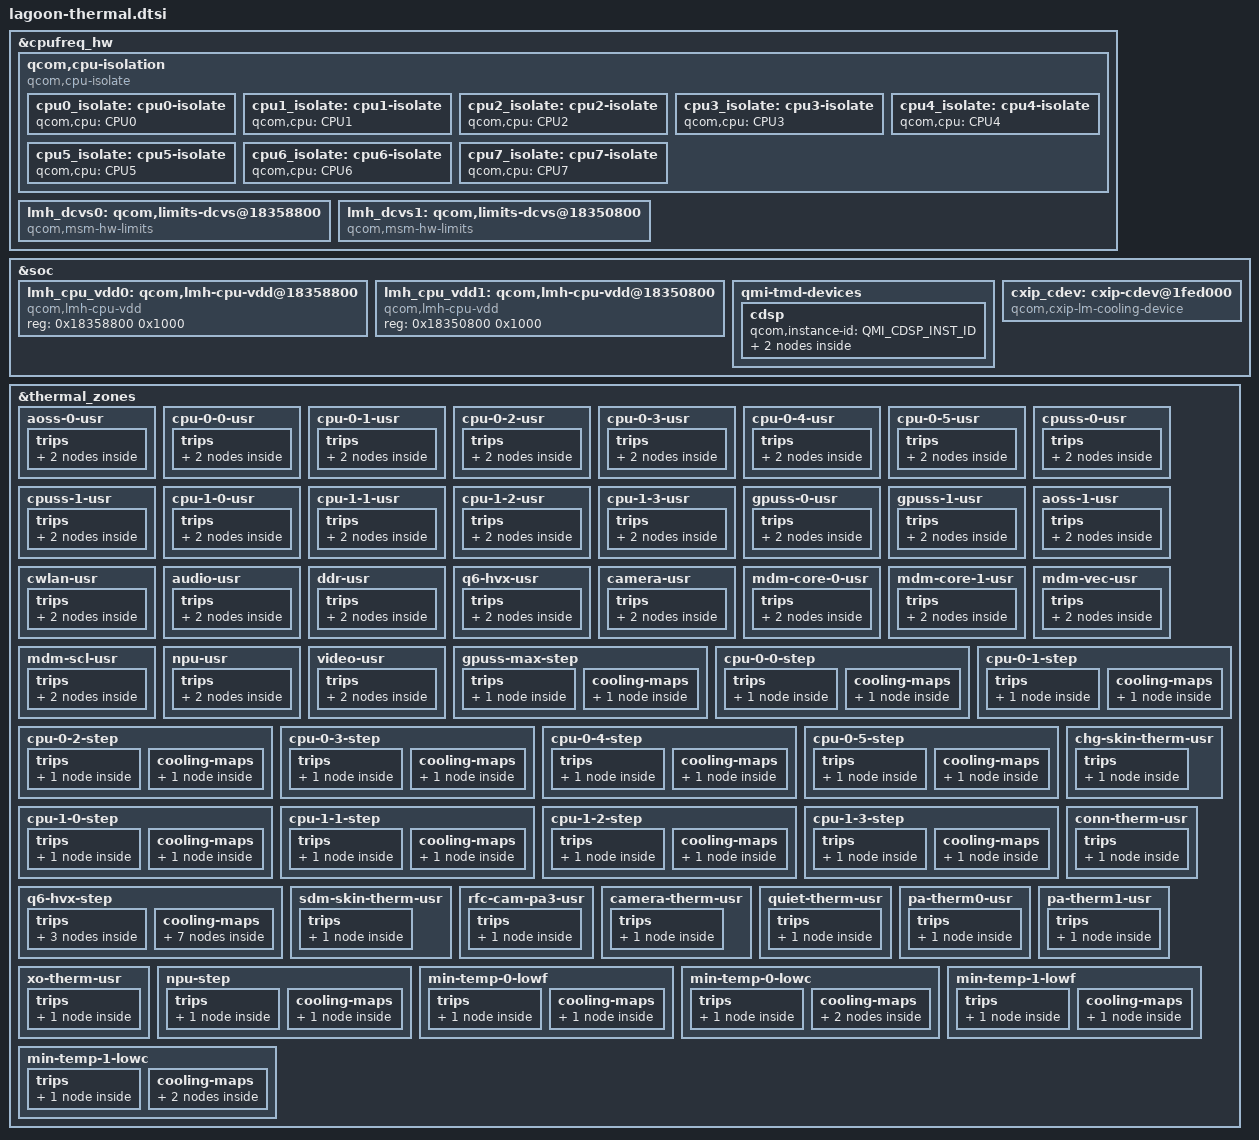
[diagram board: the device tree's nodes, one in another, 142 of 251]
#include <dt-bindings/thermal/thermal.h>
#include "sdxprairie-thermal-integrated.dtsi"

&cpufreq_hw {
	#address-cells = <1>;
	#size-cells = <1>;
	qcom,cpu-isolation {
		compatible = "qcom,cpu-isolate";
		cpu0_isolate: cpu0-isolate {
			qcom,cpu = <&CPU0>;
			#cooling-cells = <2>;
		};

		cpu1_isolate: cpu1-isolate {
			qcom,cpu = <&CPU1>;
			#cooling-cells = <2>;
		};

		cpu2_isolate: cpu2-isolate {
			qcom,cpu = <&CPU2>;
			#cooling-cells = <2>;
		};

		cpu3_isolate: cpu3-isolate {
			qcom,cpu = <&CPU3>;
			#cooling-cells = <2>;
		};

		cpu4_isolate: cpu4-isolate {
			qcom,cpu = <&CPU4>;
			#cooling-cells = <2>;
		};

		cpu5_isolate: cpu5-isolate {
			qcom,cpu = <&CPU5>;
			#cooling-cells = <2>;
		};

		cpu6_isolate: cpu6-isolate {
			qcom,cpu = <&CPU6>;
			#cooling-cells = <2>;
		};

		cpu7_isolate: cpu7-isolate {
			qcom,cpu = <&CPU7>;
			#cooling-cells = <2>;
		};
	};

	lmh_dcvs0: qcom,limits-dcvs@18358800 {
		compatible = "qcom,msm-hw-limits";
		interrupts = <GIC_SPI 32 IRQ_TYPE_LEVEL_HIGH>;
		qcom,affinity = <0>;
		reg = <0x18358800 0x1000>,
			<0x18323000 0x1000>;
		qcom,no-cooling-device-register;
	};

	lmh_dcvs1: qcom,limits-dcvs@18350800 {
		compatible = "qcom,msm-hw-limits";
		interrupts = <GIC_SPI 33 IRQ_TYPE_LEVEL_HIGH>;
		qcom,affinity = <1>;
		reg = <0x18350800 0x1000>,
			<0x18325800 0x1000>;
		qcom,no-cooling-device-register;
	};
};

&soc {
	lmh_cpu_vdd0: qcom,lmh-cpu-vdd@18358800 {
		compatible = "qcom,lmh-cpu-vdd";
		reg =  <0x18358800 0x1000>;
		#cooling-cells = <2>;
	};

	lmh_cpu_vdd1: qcom,lmh-cpu-vdd@18350800 {
		compatible = "qcom,lmh-cpu-vdd";
		reg =  <0x18350800 0x1000>;
		#cooling-cells = <2>;
	};

	qmi-tmd-devices {
		cdsp {
			qcom,instance-id = <QMI_CDSP_INST_ID>;

			cdsp_sw: cdsp {
				qcom,qmi-dev-name = "cdsp_sw";
				#cooling-cells = <2>;
			};

			cdsp_hw: hvx {
				qcom,qmi-dev-name = "cdsp_hw";
				#cooling-cells = <2>;
			};
		};
	};

	cxip_cdev: cxip-cdev@1fed000 {
		compatible = "qcom,cxip-lm-cooling-device";
		reg = <0x1fed000 0x10060>;
		qcom,thermal-client-offset = <0x8000>;
		qcom,bypass-client-list = <0xe00c 0xf00c 0x1000c 0x1001c
					0x1002c 0x1003c 0x1004c 0x1005c>;
		#cooling-cells = <2>;
	};
};

&thermal_zones {
	aoss-0-usr {
		polling-delay-passive = <0>;
		polling-delay = <0>;
		thermal-governor = "user_space";
		thermal-sensors = <&tsens0 0>;
		wake-capable-sensor;
		trips {
			active-config0 {
				temperature = <125000>;
				hysteresis = <1000>;
				type = "passive";
			};

			reset-mon-cfg {
				temperature = <115000>;
				hysteresis = <5000>;
				type = "passive";
			};
		};
	};

	cpu-0-0-usr {
		polling-delay-passive = <0>;
		polling-delay = <0>;
		thermal-governor = "user_space";
		thermal-sensors = <&tsens0 1>;
		wake-capable-sensor;
		trips {
			active-config0 {
				temperature = <125000>;
				hysteresis = <1000>;
				type = "passive";
			};

			reset-mon-cfg {
				temperature = <115000>;
				hysteresis = <5000>;
				type = "passive";
			};
		};
	};

	cpu-0-1-usr {
		polling-delay-passive = <0>;
		polling-delay = <0>;
		thermal-governor = "user_space";
		thermal-sensors = <&tsens0 2>;
		wake-capable-sensor;
		trips {
			active-config0 {
				temperature = <125000>;
				hysteresis = <1000>;
				type = "passive";
			};

			reset-mon-cfg {
				temperature = <115000>;
				hysteresis = <5000>;
				type = "passive";
			};
		};
	};

	cpu-0-2-usr {
		polling-delay-passive = <0>;
		polling-delay = <0>;
		thermal-governor = "user_space";
		thermal-sensors = <&tsens0 3>;
		wake-capable-sensor;
		trips {
			active-config0 {
				temperature = <125000>;
				hysteresis = <1000>;
				type = "passive";
			};

			reset-mon-cfg {
				temperature = <115000>;
				hysteresis = <5000>;
				type = "passive";
			};
		};
	};

	cpu-0-3-usr {
		polling-delay-passive = <0>;
		polling-delay = <0>;
		thermal-governor = "user_space";
		thermal-sensors = <&tsens0 4>;
		wake-capable-sensor;
		trips {
			active-config0 {
				temperature = <125000>;
				hysteresis = <1000>;
				type = "passive";
			};

			reset-mon-cfg {
				temperature = <115000>;
				hysteresis = <5000>;
				type = "passive";
			};
		};
	};

	cpu-0-4-usr {
		polling-delay-passive = <0>;
		polling-delay = <0>;
		thermal-governor = "user_space";
		thermal-sensors = <&tsens0 5>;
		wake-capable-sensor;
		trips {
			active-config0 {
				temperature = <125000>;
				hysteresis = <1000>;
				type = "passive";
			};

			reset-mon-cfg {
				temperature = <115000>;
				hysteresis = <5000>;
				type = "passive";
			};
		};
	};

	cpu-0-5-usr {
		polling-delay-passive = <0>;
		polling-delay = <0>;
		thermal-governor = "user_space";
		thermal-sensors = <&tsens0 6>;
		wake-capable-sensor;
		trips {
			active-config0 {
				temperature = <125000>;
				hysteresis = <1000>;
				type = "passive";
			};

			reset-mon-cfg {
				temperature = <115000>;
				hysteresis = <5000>;
				type = "passive";
			};
		};
	};

	cpuss-0-usr {
		polling-delay-passive = <0>;
		polling-delay = <0>;
		thermal-governor = "user_space";
		thermal-sensors = <&tsens0 7>;
		wake-capable-sensor;
		trips {
			active-config0 {
				temperature = <125000>;
				hysteresis = <1000>;
				type = "passive";
			};

			reset-mon-cfg {
				temperature = <115000>;
				hysteresis = <5000>;
				type = "passive";
			};
		};
	};

	cpuss-1-usr {
		polling-delay-passive = <0>;
		polling-delay = <0>;
		thermal-governor = "user_space";
		thermal-sensors = <&tsens0 8>;
		wake-capable-sensor;
		trips {
			active-config0 {
				temperature = <125000>;
				hysteresis = <1000>;
				type = "passive";
			};

			reset-mon-cfg {
				temperature = <115000>;
				hysteresis = <5000>;
				type = "passive";
			};
		};
	};

	cpu-1-0-usr {
		polling-delay-passive = <0>;
		polling-delay = <0>;
		thermal-governor = "user_space";
		thermal-sensors = <&tsens0 9>;
		wake-capable-sensor;
		trips {
			active-config0 {
				temperature = <125000>;
				hysteresis = <1000>;
				type = "passive";
			};

			reset-mon-cfg {
				temperature = <115000>;
				hysteresis = <5000>;
				type = "passive";
			};
		};
	};

	cpu-1-1-usr {
		polling-delay-passive = <0>;
		polling-delay = <0>;
		thermal-governor = "user_space";
		thermal-sensors = <&tsens0 10>;
		wake-capable-sensor;
		trips {
			active-config0 {
				temperature = <125000>;
				hysteresis = <1000>;
				type = "passive";
			};

			reset-mon-cfg {
				temperature = <115000>;
				hysteresis = <5000>;
				type = "passive";
			};
		};
	};

	cpu-1-2-usr {
		polling-delay-passive = <0>;
		polling-delay = <0>;
		thermal-governor = "user_space";
		thermal-sensors = <&tsens0 11>;
		wake-capable-sensor;
		trips {
			active-config0 {
				temperature = <125000>;
				hysteresis = <1000>;
				type = "passive";
			};

			reset-mon-cfg {
				temperature = <115000>;
				hysteresis = <5000>;
				type = "passive";
			};
		};
	};

	cpu-1-3-usr {
		polling-delay-passive = <0>;
		polling-delay = <0>;
		thermal-governor = "user_space";
		thermal-sensors = <&tsens0 12>;
		wake-capable-sensor;
		trips {
			active-config0 {
				temperature = <125000>;
				hysteresis = <1000>;
				type = "passive";
			};

			reset-mon-cfg {
				temperature = <115000>;
				hysteresis = <5000>;
				type = "passive";
			};
		};
	};

	gpuss-0-usr {
		polling-delay-passive = <0>;
		polling-delay = <0>;
		thermal-governor = "user_space";
		thermal-sensors = <&tsens0 13>;
		wake-capable-sensor;
		trips {
			active-config0 {
				temperature = <125000>;
				hysteresis = <1000>;
				type = "passive";
			};

			reset-mon-cfg {
				temperature = <115000>;
				hysteresis = <5000>;
				type = "passive";
			};
		};
	};

	gpuss-1-usr {
		polling-delay-passive = <0>;
		polling-delay = <0>;
		thermal-governor = "user_space";
		thermal-sensors = <&tsens0 14>;
		wake-capable-sensor;
		trips {
			active-config0 {
				temperature = <125000>;
				hysteresis = <1000>;
				type = "passive";
			};

			reset-mon-cfg {
				temperature = <115000>;
				hysteresis = <5000>;
				type = "passive";
			};
		};
	};

	aoss-1-usr {
		polling-delay-passive = <0>;
		polling-delay = <0>;
		thermal-governor = "user_space";
		thermal-sensors = <&tsens1 0>;
		wake-capable-sensor;
		trips {
			active-config0 {
				temperature = <125000>;
				hysteresis = <1000>;
				type = "passive";
			};

			reset-mon-cfg {
				temperature = <115000>;
				hysteresis = <5000>;
				type = "passive";
			};
		};
	};

	cwlan-usr {
		polling-delay-passive = <0>;
		polling-delay = <0>;
		thermal-governor = "user_space";
		thermal-sensors = <&tsens1 1>;
		wake-capable-sensor;
		trips {
			active-config0 {
				temperature = <125000>;
				hysteresis = <1000>;
				type = "passive";
			};

			reset-mon-cfg {
				temperature = <115000>;
				hysteresis = <5000>;
				type = "passive";
			};
		};
	};

	audio-usr {
		polling-delay-passive = <0>;
		polling-delay = <0>;
		thermal-governor = "user_space";
		thermal-sensors = <&tsens1 2>;
		wake-capable-sensor;
		trips {
			active-config0 {
				temperature = <125000>;
				hysteresis = <1000>;
				type = "passive";
			};

			reset-mon-cfg {
				temperature = <115000>;
				hysteresis = <5000>;
				type = "passive";
			};
		};
	};

	ddr-usr {
		polling-delay-passive = <0>;
		polling-delay = <0>;
		thermal-governor = "user_space";
		thermal-sensors = <&tsens1 3>;
		wake-capable-sensor;
		trips {
			active-config0 {
				temperature = <125000>;
				hysteresis = <1000>;
				type = "passive";
			};

			reset-mon-cfg {
				temperature = <115000>;
				hysteresis = <5000>;
				type = "passive";
			};
		};
	};

	q6-hvx-usr {
		polling-delay-passive = <0>;
		polling-delay = <0>;
		thermal-governor = "user_space";
		thermal-sensors = <&tsens1 4>;
		wake-capable-sensor;
		trips {
			active-config0 {
				temperature = <125000>;
				hysteresis = <1000>;
				type = "passive";
			};

			reset-mon-cfg {
				temperature = <115000>;
				hysteresis = <5000>;
				type = "passive";
			};
		};
	};

	camera-usr {
		polling-delay-passive = <0>;
		polling-delay = <0>;
		thermal-governor = "user_space";
		thermal-sensors = <&tsens1 5>;
		wake-capable-sensor;
		trips {
			active-config0 {
				temperature = <125000>;
				hysteresis = <1000>;
				type = "passive";
			};

			reset-mon-cfg {
				temperature = <115000>;
				hysteresis = <5000>;
				type = "passive";
			};
		};
	};

	mdm-core-0-usr {
		polling-delay-passive = <0>;
		polling-delay = <0>;
		thermal-governor = "user_space";
		thermal-sensors = <&tsens1 6>;
		wake-capable-sensor;
		trips {
			active-config0 {
				temperature = <125000>;
				hysteresis = <1000>;
				type = "passive";
			};

			reset-mon-cfg {
				temperature = <115000>;
				hysteresis = <5000>;
				type = "passive";
			};
		};
	};

	mdm-core-1-usr {
		polling-delay-passive = <0>;
		polling-delay = <0>;
		thermal-governor = "user_space";
		thermal-sensors = <&tsens1 7>;
		wake-capable-sensor;
		trips {
			active-config0 {
				temperature = <125000>;
				hysteresis = <1000>;
				type = "passive";
			};

			reset-mon-cfg {
				temperature = <115000>;
				hysteresis = <5000>;
				type = "passive";
			};
		};
	};

	mdm-vec-usr {
		polling-delay-passive = <0>;
		polling-delay = <0>;
		thermal-governor = "user_space";
		thermal-sensors = <&tsens1 8>;
		wake-capable-sensor;
		trips {
			active-config0 {
				temperature = <125000>;
				hysteresis = <1000>;
				type = "passive";
			};

			reset-mon-cfg {
				temperature = <115000>;
				hysteresis = <5000>;
				type = "passive";
			};
		};
	};

	mdm-scl-usr {
		polling-delay-passive = <0>;
		polling-delay = <0>;
		thermal-governor = "user_space";
		thermal-sensors = <&tsens1 9>;
		wake-capable-sensor;
		trips {
			active-config0 {
				temperature = <125000>;
				hysteresis = <1000>;
				type = "passive";
			};

			reset-mon-cfg {
				temperature = <115000>;
				hysteresis = <5000>;
				type = "passive";
			};
		};
	};

	npu-usr {
		polling-delay-passive = <0>;
		polling-delay = <0>;
		thermal-governor = "user_space";
		thermal-sensors = <&tsens1 10>;
		wake-capable-sensor;
		trips {
			active-config0 {
				temperature = <125000>;
				hysteresis = <1000>;
				type = "passive";
			};

			reset-mon-cfg {
				temperature = <115000>;
				hysteresis = <5000>;
				type = "passive";
			};
		};
	};

	video-usr {
		polling-delay-passive = <0>;
		polling-delay = <0>;
		thermal-governor = "user_space";
		thermal-sensors = <&tsens1 11>;
		wake-capable-sensor;
		trips {
			active-config0 {
				temperature = <125000>;
				hysteresis = <1000>;
				type = "passive";
			};

			reset-mon-cfg {
				temperature = <115000>;
				hysteresis = <5000>;
				type = "passive";
			};
		};
	};

	gpuss-max-step {
		polling-delay-passive = <10>;
		polling-delay = <100>;
		thermal-governor = "step_wise";
		wake-capable-sensor;
		trips {
			gpu_trip0: gpu-trip0 {
				temperature = <95000>;
				hysteresis = <0>;
				type = "passive";
			};
		};

		cooling-maps {
			gpu_cdev {
				trip = <&gpu_trip0>;
				cooling-device = <&msm_gpu THERMAL_NO_LIMIT
							THERMAL_NO_LIMIT>;
			};
		};
	};

	cpu-0-0-step {
		polling-delay-passive = <0>;
		polling-delay = <0>;
		thermal-governor = "step_wise";
		thermal-sensors = <&tsens0 1>;
		wake-capable-sensor;
		trips {
			cpu00_config: cpu00-config {
				temperature = <110000>;
				hysteresis = <10000>;
				type = "passive";
			};
		};

		cooling-maps {
			cpu00_cdev {
				trip = <&cpu00_config>;
				cooling-device = <&cpu0_isolate 1 1>;
			};
		};
	};

	cpu-0-1-step {
		polling-delay-passive = <0>;
		polling-delay = <0>;
		thermal-governor = "step_wise";
		thermal-sensors = <&tsens0 2>;
		wake-capable-sensor;
		trips {
			cpu01_config: cpu01-config {
				temperature = <110000>;
				hysteresis = <10000>;
				type = "passive";
			};
		};

		cooling-maps {
			cpu01_cdev {
				trip = <&cpu01_config>;
				cooling-device = <&cpu1_isolate 1 1>;
			};
		};
	};

	cpu-0-2-step {
		polling-delay-passive = <0>;
		polling-delay = <0>;
		thermal-governor = "step_wise";
		thermal-sensors = <&tsens0 3>;
		wake-capable-sensor;
		trips {
			cpu02_config: cpu02-config {
				temperature = <110000>;
				hysteresis = <10000>;
				type = "passive";
			};
		};

		cooling-maps {
			cpu02_cdev {
				trip = <&cpu02_config>;
				cooling-device = <&cpu2_isolate 1 1>;
			};
		};
	};

	cpu-0-3-step {
		polling-delay-passive = <0>;
		polling-delay = <0>;
		thermal-sensors = <&tsens0 4>;
		thermal-governor = "step_wise";
		wake-capable-sensor;
		trips {
			cpu03_config: cpu03-config {
				temperature = <110000>;
				hysteresis = <10000>;
				type = "passive";
			};
		};

		cooling-maps {
			cpu03_cdev {
				trip = <&cpu03_config>;
				cooling-device = <&cpu3_isolate 1 1>;
			};
		};
	};

	cpu-0-4-step {
		polling-delay-passive = <0>;
		polling-delay = <0>;
		thermal-sensors = <&tsens0 5>;
		thermal-governor = "step_wise";
		wake-capable-sensor;
		trips {
			cpu04_config: cpu04-config {
				temperature = <110000>;
				hysteresis = <10000>;
				type = "passive";
			};
		};

		cooling-maps {
			cpu04_cdev {
				trip = <&cpu04_config>;
				cooling-device = <&cpu4_isolate 1 1>;
			};
		};
	};

	cpu-0-5-step {
		polling-delay-passive = <0>;
		polling-delay = <0>;
		thermal-sensors = <&tsens0 6>;
		thermal-governor = "step_wise";
		wake-capable-sensor;
		trips {
			cpu05_config: cpu05-config {
				temperature = <110000>;
				hysteresis = <10000>;
				type = "passive";
			};
		};

		cooling-maps {
			cpu05_cdev {
				trip = <&cpu05_config>;
				cooling-device = <&cpu5_isolate 1 1>;
			};
		};
	};

	cpu-1-0-step {
		polling-delay-passive = <0>;
		polling-delay = <0>;
		thermal-sensors = <&tsens0 9>;
		thermal-governor = "step_wise";
		wake-capable-sensor;
		trips {
			cpu10_config: cpu10-config {
				temperature = <110000>;
				hysteresis = <10000>;
				type = "passive";
			};
		};

		cooling-maps {
			cpu10_cdev {
				trip = <&cpu10_config>;
				cooling-device = <&cpu6_isolate 1 1>;
			};
		};
	};

	cpu-1-1-step {
		polling-delay-passive = <0>;
		polling-delay = <0>;
		thermal-sensors = <&tsens0 10>;
		thermal-governor = "step_wise";
		wake-capable-sensor;
		trips {
			cpu11_config: cpu11-config {
				temperature = <110000>;
				hysteresis = <10000>;
				type = "passive";
			};
		};

		cooling-maps {
			cpu11_cdev {
				trip = <&cpu11_config>;
				cooling-device = <&cpu6_isolate 1 1>;
			};
		};
	};

	cpu-1-2-step {
		polling-delay-passive = <0>;
		polling-delay = <0>;
		thermal-sensors = <&tsens0 11>;
		thermal-governor = "step_wise";
		wake-capable-sensor;
		trips {
			cpu12_config: cpu12-config {
				temperature = <110000>;
				hysteresis = <10000>;
				type = "passive";
			};
		};

		cooling-maps {
			cpu12_cdev {
				trip = <&cpu12_config>;
				cooling-device = <&cpu7_isolate 1 1>;
			};
		};
	};

	cpu-1-3-step {
		polling-delay-passive = <0>;
		polling-delay = <0>;
		thermal-sensors = <&tsens0 12>;
		thermal-governor = "step_wise";
		wake-capable-sensor;
		trips {
			cpu13_config: cpu13-config {
				temperature = <110000>;
				hysteresis = <10000>;
				type = "passive";
			};
		};

		cooling-maps {
			cpu13_cdev {
				trip = <&cpu13_config>;
				cooling-device = <&cpu7_isolate 1 1>;
			};
		};
	};

	q6-hvx-step {
		polling-delay-passive = <10>;
		polling-delay = <0>;
		thermal-sensors = <&tsens1 4>;
		thermal-governor = "step_wise";
		wake-capable-sensor;
		trips {
			cxip_trip: cxip-trip {
				temperature = <95000>;
				hysteresis = <20000>;
				type = "passive";
			};

			q6_hvx_trip0: q6-hvx-trip0 {
				temperature = <95000>;
				hysteresis = <0>;
				type = "passive";
			};

			q6_hvx_trip1: q6-hvx-trip1 {
				temperature = <100000>;
				hysteresis = <5000>;
				type = "passive";
			};
		};

		cooling-maps {
			cxip-cdev {
				trip = <&cxip_trip>;
				cooling-device = <&cxip_cdev 1 1>;
			};

			cdsp-cdev0 {
				trip = <&q6_hvx_trip0>;
				cooling-device = <&cdsp_sw THERMAL_NO_LIMIT
							THERMAL_NO_LIMIT>;
			};

			cdsp-cdev1 {
				trip = <&q6_hvx_trip1>;
				cooling-device = <&cdsp_sw THERMAL_MAX_LIMIT
							THERMAL_MAX_LIMIT>;
			};

			modem-pa-cdev {
				trip = <&q6_hvx_trip1>;
				cooling-device = <&modem_pa 3 3>;
			};

			modem-tj-cdev {
				trip = <&q6_hvx_trip1>;
				cooling-device = <&modem_tj 3 3>;
			};

			npu_cdev {
				trip = <&q6_hvx_trip1>;
				cooling-device = <&msm_npu THERMAL_MAX_LIMIT
							THERMAL_MAX_LIMIT>;
			};

			gpu-cdev {
				trip = <&q6_hvx_trip1>;
				cooling-device = <&msm_gpu (THERMAL_MAX_LIMIT-1)
							(THERMAL_MAX_LIMIT-1)>;
			};
		};
	};

	chg-skin-therm-usr {
		polling-delay-passive = <0>;
		polling-delay = <0>;
		thermal-governor = "user_space";
		thermal-sensors = <&pm7250b_adc_tm ADC_AMUX_THM1_PU2>;
		wake-capable-sensor;
		trips {
			active-config0 {
				temperature = <125000>;
				hysteresis = <1000>;
				type = "passive";
			};
		};
	};

	conn-therm-usr {
		polling-delay-passive = <0>;
		polling-delay = <0>;
		thermal-governor = "user_space";
		thermal-sensors = <&pm7250b_adc_tm ADC_AMUX_THM3_PU2>;
		wake-capable-sensor;
		trips {
			active-config0 {
				temperature = <125000>;
				hysteresis = <1000>;
				type = "passive";
			};
		};
	};

	sdm-skin-therm-usr {
		polling-delay-passive = <0>;
		polling-delay = <0>;
		thermal-governor = "user_space";
		thermal-sensors = <&pm6150l_adc_tm ADC_AMUX_THM2_PU2>;
		wake-capable-sensor;
		trips {
			active-config0 {
				temperature = <125000>;
				hysteresis = <1000>;
				type = "passive";
			};
		};
	};

	rfc-cam-pa3-usr {
		polling-delay-passive = <0>;
		polling-delay = <0>;
		thermal-governor = "user_space";
		thermal-sensors = <&pm6150l_adc_tm_iio ADC_GPIO2_PU2>;
		wake-capable-sensor;
		trips {
			active-config0 {
				temperature = <125000>;
				hysteresis = <1000>;
				type = "passive";
			};
		};
	};

	camera-therm-usr {
		polling-delay-passive = <0>;
		polling-delay = <0>;
		thermal-governor = "user_space";
		thermal-sensors = <&pm6150l_adc_tm ADC_GPIO3_PU2>;
		wake-capable-sensor;
		trips {
			active-config0 {
				temperature = <125000>;
				hysteresis = <1000>;
				type = "passive";
			};
		};
	};

	quiet-therm-usr {
		polling-delay-passive = <0>;
		polling-delay = <0>;
		thermal-governor = "user_space";
		thermal-sensors = <&pm6150l_adc_tm_iio ADC_GPIO4_PU2>;
		wake-capable-sensor;
		trips {
			active-config0 {
				temperature = <125000>;
				hysteresis = <1000>;
				type = "passive";
			};
		};
	};

	pa-therm0-usr {
		polling-delay-passive = <0>;
		polling-delay = <0>;
		thermal-governor = "user_space";
		thermal-sensors = <&pm6150l_adc_tm ADC_AMUX_THM3_PU2>;
		wake-capable-sensor;
		trips {
			active-config0 {
				temperature = <125000>;
				hysteresis = <1000>;
				type = "passive";
			};
		};
	};

	pa-therm1-usr {
		polling-delay-passive = <0>;
		polling-delay = <0>;
		thermal-governor = "user_space";
		thermal-sensors = <&pm6150l_adc_tm ADC_AMUX_THM1_PU2>;
		wake-capable-sensor;
		trips {
			active-config0 {
				temperature = <125000>;
				hysteresis = <1000>;
				type = "passive";
			};
		};
	};

	xo-therm-usr {
		polling-delay-passive = <0>;
		polling-delay = <0>;
		thermal-governor = "user_space";
		thermal-sensors = <&pmk8350_adc_tm PMK8350_ADC7_AMUX_THM1_100K_PU>;
		wake-capable-sensor;
		trips {
			active-config0 {
				temperature = <125000>;
				hysteresis = <1000>;
				type = "passive";
			};
		};
	};

	npu-step {
		polling-delay-passive = <10>;
		polling-delay = <0>;
		thermal-sensors = <&tsens1 10>;
		thermal-governor = "step_wise";
		wake-capable-sensor;
		trips {
			npu_trip0: npu-trip0 {
				temperature = <95000>;
				hysteresis = <0>;
				type = "passive";
			};
		};

		cooling-maps {
			npu_cdev {
				trip = <&npu_trip0>;
				cooling-device =
					<&msm_npu THERMAL_NO_LIMIT
						THERMAL_NO_LIMIT>;
			};
		};
	};

	min-temp-0-lowf {
		polling-delay-passive = <0>;
		polling-delay = <0>;
		thermal-sensors = <&tsens0 16>;
		thermal-governor = "low_limits_floor";
		wake-capable-sensor;
		tracks-low;
		trips {
			min_temp_0_lowf: active-config0 {
				temperature = <5000>;
				hysteresis = <5000>;
				type = "passive";
			};
		};

		cooling-maps {
			wcss_cx_vdd_cdev {
				trip = <&min_temp_0_lowf>;
				cooling-device = <&cx_cdev 0 0>;
			};
		};
	};

	min-temp-0-lowc {
		polling-delay-passive = <0>;
		polling-delay = <0>;
		thermal-sensors = <&tsens0 16>;
		thermal-governor = "low_limits_cap";
		wake-capable-sensor;
		tracks-low;
		trips {
			min_temp_0_lowc: active-config0 {
				temperature = <5000>;
				hysteresis = <5000>;
				type = "passive";
			};
		};

		cooling-maps {
			lmh_cpu0_cdev {
				trip = <&min_temp_0_lowc>;
				cooling-device = <&lmh_cpu_vdd0 1 1>;
			};

			lmh_cpu6_cdev {
				trip = <&min_temp_0_lowc>;
				cooling-device = <&lmh_cpu_vdd1 1 1>;
			};
		};
	};

	min-temp-1-lowf {
		polling-delay-passive = <0>;
		polling-delay = <0>;
		thermal-sensors = <&tsens1 16>;
		thermal-governor = "low_limits_floor";
		wake-capable-sensor;
		tracks-low;
		trips {
			min_temp_1_lowf: active-config0 {
				temperature = <5000>;
				hysteresis = <5000>;
				type = "passive";
			};
		};

		cooling-maps {
			wcss_cx_vdd_cdev {
				trip = <&min_temp_1_lowf>;
				cooling-device = <&cx_cdev 0 0>;
			};
		};
	};

	min-temp-1-lowc {
		polling-delay-passive = <0>;
		polling-delay = <0>;
		thermal-sensors = <&tsens1 16>;
		thermal-governor = "low_limits_cap";
		wake-capable-sensor;
		tracks-low;
		trips {
			min_temp_1_lowc: active-config0 {
				temperature = <5000>;
				hysteresis = <5000>;
				type = "passive";
			};
		};

		cooling-maps {
			lmh_cpu0_cdev {
				trip = <&min_temp_1_lowc>;
				cooling-device = <&lmh_cpu_vdd0 1 1>;
			};

			lmh_cpu6_cdev {
				trip = <&min_temp_1_lowc>;
				cooling-device = <&lmh_cpu_vdd1 1 1>;
			};
		};
	};
};
